AUTOSAR XML (schema 4.0)
package /Powertrain_Components
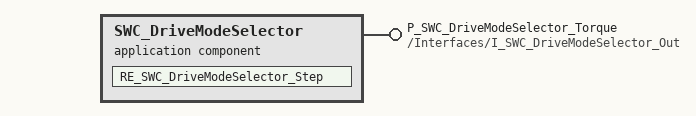
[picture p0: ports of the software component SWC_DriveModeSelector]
  application sw component type SWC_DriveModeSelector  # AUTOSAR Application SWC SWC_DriveModeSelector for Powertrain Control
    provide port P_SWC_DriveModeSelector_Torque: provided-interface=/Interfaces/I_SWC_DriveModeSelector_Out
    behavior SWC_DriveModeSelector_Behavior
      runnable RE_SWC_DriveModeSelector_Step: symbol=SWC_DriveModeSelector_Step
  sender receiver interface I_SWC_DriveModeSelector_Out
    data DE_SWC_DriveModeSelector_TorqueDemand: type=/AUTOSAR/Platform/uint32
